AUTOSAR XML (schema 00049)
package /Components
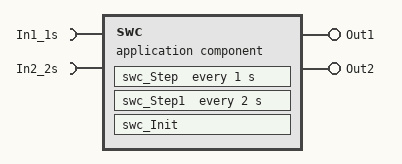
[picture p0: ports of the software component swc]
  application sw component type swc
    require port In1_1s: nonqueued-receiver-com-spec{data-element=In1_1s, init-value=0}, required-interface=In1_1s
    require port In2_2s: nonqueued-receiver-com-spec{data-element=In2_2s, init-value=0}, required-interface=In2_2s
    provide port Out1: nonqueued-sender-com-spec{data-element=Out1, init-value=0}, provided-interface=Out1
    provide port Out2: nonqueued-sender-com-spec{data-element=Out2, init-value=0}, provided-interface=Out2
    behavior swc_IB: handle-termination-and-restart=NO-SUPPORT
      timing event Event_swc_Step: start-on-event=swc_Step, period=1
      timing event Event_swc_Step1: start-on-event=swc_Step1, period=2
      implicit-inter-runnable-variables:
        data IRV1: category=VALUE, sw-calibration-access=READ-ONLY, type=Double, init-value=0
      runnable swc_Init
      runnable swc_Step
        data-read-access:
          access IN_In1_1s_In1_1s: accessed-variable=In1_1s.In1_1s
        data-write-access:
          access OUT_Out1_Out1: accessed-variable=Out1.Out1
          access OUT_Out2_Out2: accessed-variable=Out2.Out2
        read-local-variables:
          access RV_IRV1: accessed-variable=IRV1
      runnable swc_Step1
        data-read-access:
          access IN_In2_2s_In2_2s: accessed-variable=In2_2s.In2_2s
        written-local-variables:
          access WV_IRV1: accessed-variable=IRV1
